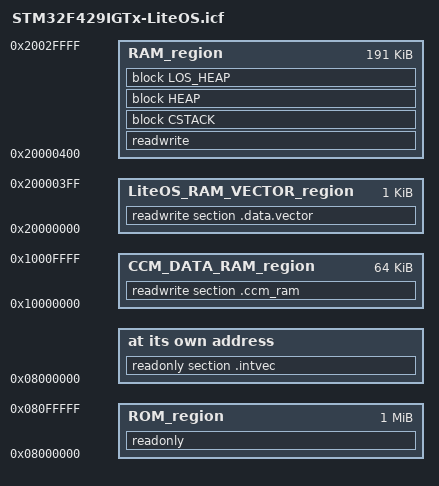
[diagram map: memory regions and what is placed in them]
/*###ICF### Section handled by ICF editor, don't touch! ****/
/*-Editor annotation file-*/
/* IcfEditorFile="$TOOLKIT_DIR$\config\ide\IcfEditor\cortex_v1_0.xml" */
/*-Specials-*/
define symbol __ICFEDIT_intvec_start__ = 0x08000000;
/*-Memory Regions-*/
define symbol __ICFEDIT_region_ROM_start__    = 0x08000000;
define symbol __ICFEDIT_region_ROM_end__      = 0x080FFFFF;
/*****huawei LiteOS interrupt vector in ram region******/
define symbol __LITEOS_RAM_VECTOR_start__     = 0x20000000;
define symbol __LITEOS_RAM_VECTOR_end__       = 0x200003FF;
define symbol __ICFEDIT_region_RAM_start__    = 0x20000400;
define exported symbol __ICFEDIT_region_RAM_end__      = 0x2002FFFF;

define symbol __ICFEDIT_region_CCM_DATA_RAM_start__    = 0x10000000;
define symbol __ICFEDIT_region_CCM_DATA_RAM_end__      = 0x1000FFFF;
/*-Sizes-*/
define symbol __ICFEDIT_size_cstack__ = 0x400;
define symbol __ICFEDIT_size_heap__   = 0x200;
define symbol __ICFEDIT_size_los_min_heap__  = 0x400;
/**** End of ICF editor section. ###ICF###*/


define memory mem with size = 4G;
define region ROM_region      = mem:[from __ICFEDIT_region_ROM_start__   to __ICFEDIT_region_ROM_end__];
/*****huawei LiteOS interrupt vector in ram region******/
define region LiteOS_RAM_VECTOR_region = mem:[from __LITEOS_RAM_VECTOR_start__ to __LITEOS_RAM_VECTOR_end__];
define region RAM_region      = mem:[from __ICFEDIT_region_RAM_start__   to __ICFEDIT_region_RAM_end__];
define region CCM_DATA_RAM_region =mem:[from __ICFEDIT_region_CCM_DATA_RAM_start__  to  __ICFEDIT_region_CCM_DATA_RAM_end__];

define block CSTACK    with alignment = 8, size = __ICFEDIT_size_cstack__   { };
define block HEAP      with alignment = 8, size = __ICFEDIT_size_heap__     { };
define block LOS_HEAP  with alignment = 8, size = __ICFEDIT_size_los_min_heap__ { };

initialize by copy { readwrite };
do not initialize  { section .noinit };

place at address mem:__ICFEDIT_intvec_start__ { readonly section .intvec };

/*****huawei LiteOS interrupt vector in ram region******/
place in LiteOS_RAM_VECTOR_region { readwrite section .data.vector };

place in ROM_region   { readonly };
place in RAM_region   { readwrite,
                        block CSTACK, block HEAP, block LOS_HEAP };
place in CCM_DATA_RAM_region  { readwrite section .ccm_ram };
